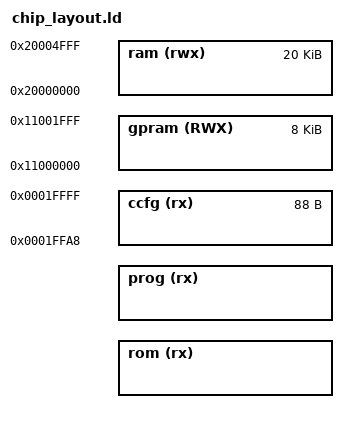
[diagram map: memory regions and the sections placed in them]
MEMORY
{
  rom (rx)  : ORIGIN = ROM_BEG, LENGTH = ROM_LEN
  prog (rx) : ORIGIN = PROG_BEG, LENGTH = PROG_LEN
  ccfg (rx) : ORIGIN = 0x0001FFA8, LENGTH = 88
  ram (rwx) : ORIGIN = 0x20000000, LENGTH = 0x00005000
  gpram(RWX): ORIGIN = 0x11000000, LENGTH = 0x00002000
}

MPU_MIN_ALIGN = 4K;
